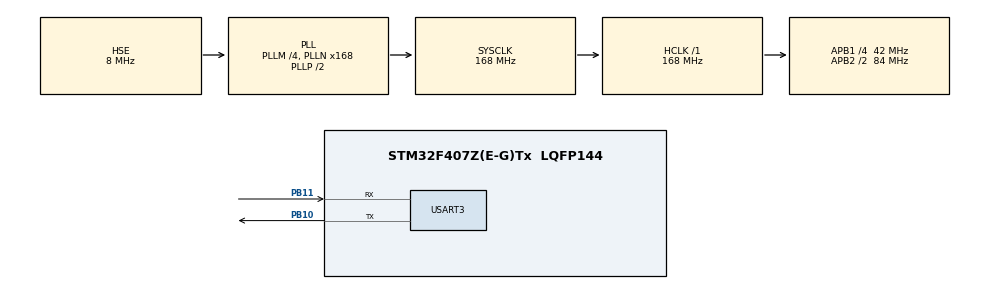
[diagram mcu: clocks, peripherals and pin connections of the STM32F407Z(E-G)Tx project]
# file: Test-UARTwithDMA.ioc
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Dma.Request0=USART3_RX
Dma.USART3_RX.0.Direction=DMA_PERIPH_TO_MEMORY
Dma.USART3_RX.0.FIFOMode=DMA_FIFOMODE_DISABLE
Dma.USART3_RX.0.Instance=DMA1_Stream1
Dma.USART3_RX.0.MemDataAlignment=DMA_MDATAALIGN_BYTE
Dma.USART3_RX.0.MemInc=DMA_MINC_ENABLE
Dma.USART3_RX.0.Mode=DMA_CIRCULAR
Dma.USART3_RX.0.PeriphDataAlignment=DMA_PDATAALIGN_BYTE
Dma.USART3_RX.0.PeriphInc=DMA_PINC_DISABLE
Dma.USART3_RX.0.Priority=DMA_PRIORITY_MEDIUM
Mcu.Family=STM32F4
Mcu.Name=STM32F407Z(E-G)Tx
Mcu.Package=LQFP144
NVIC.DMA1_Stream1_IRQn=true\:0\:0\:false\:false\:true\:false\:true\:true
NVIC.PriorityGroup=NVIC_PRIORITYGROUP_4
NVIC.USART3_IRQn=true\:1\:0\:true\:false\:true\:true\:true\:true
PA13.Mode=Serial_Wire
PA13.Signal=SYS_JTMS-SWDIO
PA14.Mode=Serial_Wire
PA14.Signal=SYS_JTCK-SWCLK
PB10.Mode=Asynchronous
PB10.Signal=USART3_TX
PB11.Mode=Asynchronous
PB11.Signal=USART3_RX
PH0-OSC_IN.Mode=HSE-External-Oscillator
PH0-OSC_IN.Signal=RCC_OSC_IN
PH1-OSC_OUT.Mode=HSE-External-Oscillator
PH1-OSC_OUT.Signal=RCC_OSC_OUT
ProjectManager.HeapSize=0x200
ProjectManager.StackSize=0x400
ProjectManager.TargetToolchain=MDK-ARM V5.32
RCC.48MHZClocksFreq_Value=84000000
RCC.AHBFreq_Value=168000000
RCC.APB1CLKDivider=RCC_HCLK_DIV4
RCC.APB1Freq_Value=42000000
RCC.APB1TimFreq_Value=84000000
RCC.APB2CLKDivider=RCC_HCLK_DIV2
RCC.APB2Freq_Value=84000000
RCC.APB2TimFreq_Value=168000000
RCC.CortexFreq_Value=168000000
RCC.HCLKFreq_Value=168000000
RCC.HSE_VALUE=8000000
RCC.HSI_VALUE=16000000
RCC.LSE_VALUE=32768
RCC.PLLM=4
RCC.PLLN=168
RCC.PLLSourceVirtual=RCC_PLLSOURCE_HSE
RCC.SYSCLKFreq_VALUE=168000000
RCC.SYSCLKSource=RCC_SYSCLKSOURCE_PLLCLK
RCC.VCOOutputFreq_Value=336000000
USART3.VirtualMode=VM_ASYNC
board=custom

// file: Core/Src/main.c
/* USER CODE BEGIN Header */
/**
  ******************************************************************************
  * @file           : main.c
  * @brief          : Main program body
  ******************************************************************************
  * @attention
  *
  * Copyright (c) 2026 STMicroelectronics.
  * All rights reserved.
  *
  * This software is licensed under terms that can be found in the LICENSE file
  * in the root directory of this software component.
  * If no LICENSE file comes with this software, it is provided AS-IS.
  *
  ******************************************************************************
  */
/* USER CODE END Header */
#include "main.h"
#include "dma.h"
#include "usart.h"
#include "gpio.h"

void SystemClock_Config(void);

/* USER CODE BEGIN 0 */
/**
 * @brief  串口发送一个字节，阻塞方式。
 * @note   等待发送缓冲区为空，再发送。
 * @param  huart: USART handle
 * @param  abyte: 待发送的字节
 * @retval None
 */
void uart_send_byte_blocking(UART_HandleTypeDef *huart, uint8_t abyte) {
  while ( !__HAL_UART_GET_FLAG(huart, UART_FLAG_TXE) ); // TX不为空，则持续循环
  huart->Instance->DR = abyte; // TX为空了，则跳出以上while循环发送字节
}

/**
 * @brief  串口发送一个字节数组，阻塞方式。
 * @note   等待发送缓冲区为空，再发送。
 * @attention 这个函数可以发送带有'\0'(0x00)的字节串
 * @param  huart: USART handle
 * @param  array: 待发送的字节数组
 * @param  len: 待发送的字节数组长度
 * @retval None
 */
void uart_send_array(UART_HandleTypeDef *huart, uint8_t *array, size_t len) {
  for (size_t i=0; i<len; i++) {
    uart_send_byte_blocking(huart, array[i]);
  }
}

/**
 * @brief  串口发送一个字符串，阻塞方式。
 * @note   等待发送缓冲区为空，再发送。
 * @attention 这个函数不可以发送带有'\0'(0x00)的字节串
 * @param  huart: USART handle
 * @param  string: 待发送的字符串
 * @retval None
 */
void uart_send_string(UART_HandleTypeDef *huart, char *string) {
  uart_send_array(huart, (uint8_t *)string, strlen(string));
}

/**
 * @brief  串口printf函数，用于向串口发送格式化字符串信息。
 * @note   最大长度为128字节。
 * @attention 这个函数不可以发送带有'\0'(0x00)的字节串
 * @param  huart: USART handle
 * @param  format: format string
 * @param  ...: arguments list
 * @retval None
 */
#define USART_DATALEN_MAX  256
void uart_printf(UART_HandleTypeDef *huart, char *format, ...) {
  char SendBuf[USART_DATALEN_MAX];
  va_list args;
  va_start(args, format);
  vsnprintf(SendBuf, sizeof(SendBuf), format, args);
  va_end(args);
  for (uint16_t i=0; SendBuf[i]!='\0'; i++) {
    uart_send_byte_blocking(huart, SendBuf[i]);
  }
}

UartIdleDmaRx_t ttUIDR;
/* USER CODE END 0 */

int main(void)
{

  /* MCU Configuration--------------------------------------------------------*/

  /* Reset of all peripherals, Initializes the Flash interface and the Systick. */
  HAL_Init();

  /* Configure the system clock */
  SystemClock_Config();

  /* Initialize all configured peripherals */
  MX_GPIO_Init();
  MX_DMA_Init();
  MX_USART3_UART_Init();
  /* USER CODE BEGIN 2 */
  UartIdleDmaRx_Init(&ttUIDR, &huart3, &hdma_usart3_rx);
  /* USER CODE END 2 */

  /* Infinite loop */
  /* USER CODE BEGIN WHILE */
  while (1) {
    if (UartIdleDmaRx_GetRecvFlag(&ttUIDR)) { // 获取是否接收数据标志位
      size_t rx_count = UartIdleDmaRx_GetRecvLen(&ttUIDR); // 获取接收的字节数
      uint8_t *rx_buf = UartIdleDmaRx_GetRecvBuf(&ttUIDR); // 获取接收的字节数组

      uart_printf(&huart3, "rx_count: %d\r\nrx_data: ", rx_count);
      uart_send_array(&huart3, rx_buf, rx_count);
      uart_printf(&huart3, "\r\n");
    }
    /* USER CODE END WHILE */

  }
}

void SystemClock_Config(void)
{
  RCC_OscInitTypeDef RCC_OscInitStruct = {0};
  RCC_ClkInitTypeDef RCC_ClkInitStruct = {0};

  /** Configure the main internal regulator output voltage
  */
  __HAL_RCC_PWR_CLK_ENABLE();
  __HAL_PWR_VOLTAGESCALING_CONFIG(PWR_REGULATOR_VOLTAGE_SCALE1);

  /** Initializes the RCC Oscillators according to the specified parameters
  * in the RCC_OscInitTypeDef structure.
  */
  RCC_OscInitStruct.OscillatorType = RCC_OSCILLATORTYPE_HSE;
  RCC_OscInitStruct.HSEState = RCC_HSE_ON;
  RCC_OscInitStruct.PLL.PLLState = RCC_PLL_ON;
  RCC_OscInitStruct.PLL.PLLSource = RCC_PLLSOURCE_HSE;
  RCC_OscInitStruct.PLL.PLLM = 4;
  RCC_OscInitStruct.PLL.PLLN = 168;
  RCC_OscInitStruct.PLL.PLLP = RCC_PLLP_DIV2;
  RCC_OscInitStruct.PLL.PLLQ = 4;
  if (HAL_RCC_OscConfig(&RCC_OscInitStruct) != HAL_OK)
  {
    Error_Handler();
  }

  /** Initializes the CPU, AHB and APB buses clocks
  */
  RCC_ClkInitStruct.ClockType = RCC_CLOCKTYPE_HCLK|RCC_CLOCKTYPE_SYSCLK
                              |RCC_CLOCKTYPE_PCLK1|RCC_CLOCKTYPE_PCLK2;
  RCC_ClkInitStruct.SYSCLKSource = RCC_SYSCLKSOURCE_PLLCLK;
  RCC_ClkInitStruct.AHBCLKDivider = RCC_SYSCLK_DIV1;
  RCC_ClkInitStruct.APB1CLKDivider = RCC_HCLK_DIV4;
  RCC_ClkInitStruct.APB2CLKDivider = RCC_HCLK_DIV2;

  if (HAL_RCC_ClockConfig(&RCC_ClkInitStruct, FLASH_LATENCY_5) != HAL_OK)
  {
    Error_Handler();
  }
}

void Error_Handler(void)
{
  __disable_irq();
  while (1)
  {
  }
}
